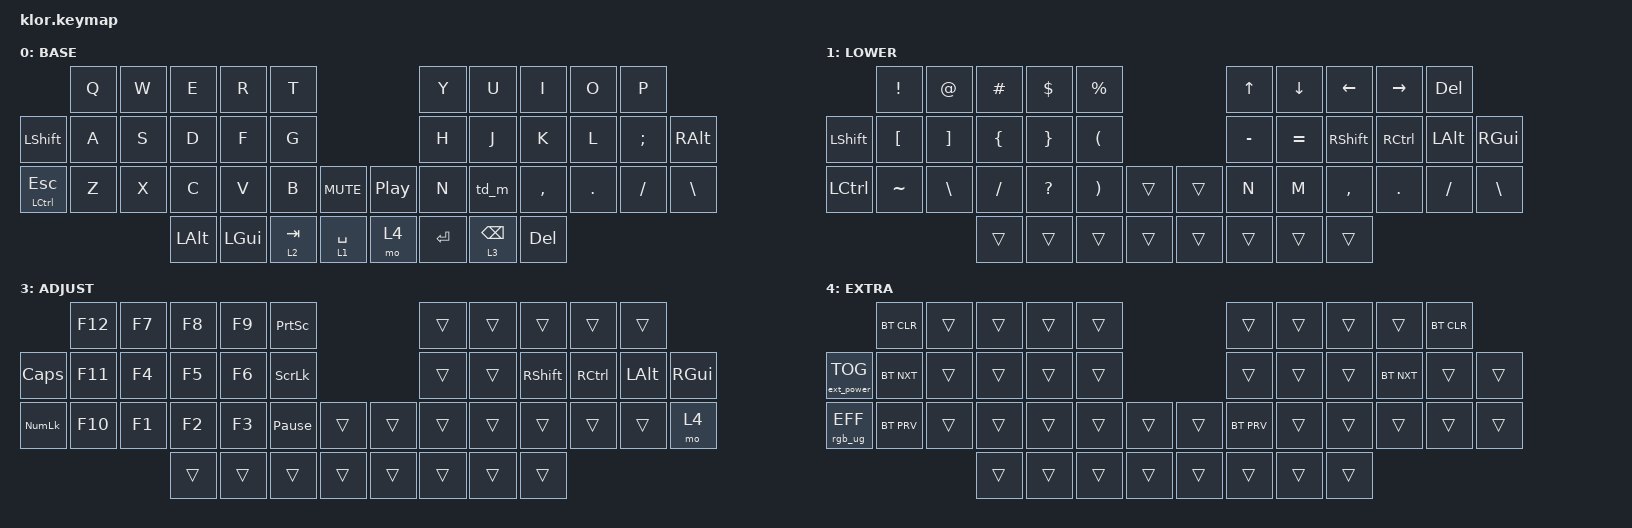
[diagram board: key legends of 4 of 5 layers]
//                               █         █    █            ▄▄▄▀▀▀▀▀▀▄▄▄        █▀▀▀▀▀▀▀▀▀▀█
//                               █        █     █          ▄▀            ▀▄      █          █
//                               █       █      █        ▄▀                ▀▄    █          █
//                               █      █       █        █                  █    █          █
//                               █     █        █       █                    █   █          █
//                               █    █         █       █                    █   █▄▄▄▄▄▄▄▄▄▄█
//                               █   █ █        █       █                    █   █      █
//                               █  █   █       █        █                  █    █       █
//                               █ █     █      █        ▀▄                ▄▀    █        █
//                               ██       █     █          ▀▄            ▄▀      █         █
//                               █         █    █▄▄▄▄▄▄▄▄    ▀▀▀▄▄▄▄▄▄▀▀▀        █          █
//
// ▄▄▄▄▄▄▄▄▄▄▄▄▄▄▄▄▄▄▄▄▄▄▄▄▄▄▄▄▄▄▄▄▄▄▄▄▄▄▄▄▄▄▄▄▄▄▄▄▄▄▄▄▄▄▄▄▄▄▄▄▄▄▄▄▄▄▄▄▄▄▄▄▄▄▄▄▄▄▄▄▄▄▄▄▄▄▄▄▄▄▄▄▄▄▄▄▄▄▄▄▄▄▄▄▄▄▄▄▄▄▄▄▄▄▄▄▄▄▄▄▄▄▄▄▄

#include <behaviors.dtsi>
#include <dt-bindings/zmk/bt.h>
#include <dt-bindings/zmk/ext_power.h>
#include <dt-bindings/zmk/keys.h>
#include <dt-bindings/zmk/rgb.h>

#define BASE   0
#define LOWER  1
#define RAISE  2
#define ADJUST 3
#define EXTRA  4

/ {
    behaviors {
        // Tap-Dance для клавиши M: 1 нажатие = M, 2 нажатия = Ъ (])
        td_m: tap_dance_m {
            compatible = "zmk,behavior-tap-dance";
            #binding-cells = <0>;
            tapping-term-ms = <200>;
            bindings = <&kp M>, <&kp RBRC>;
        };

        // Макрос для смены языка (Win+Space)
        lang_sw: lang_switch {
            compatible = "zmk,behavior-macro";
            #binding-cells = <0>;
            bindings = 
                <&macro_press &kp LGUI>,
                <&macro_tap &kp SPACE>,
                <&macro_release &kp LGUI>;
        };
    };

    combos {
        compatible = "zmk,combos";

        // Комбо Q+E (позиции 0 и 2)
        combo_lang {
            timeout-ms = <100>;
            key-positions = <0 2>;
            bindings = <&lang_sw>;
        };
    };

    keymap {
        compatible = "zmk,keymap";

        // ==========================================
        // Layer 0 (BASE)
        // ==========================================
        base_layer {
            label = "BASE";
            bindings = <
                &kp Q  &kp W  &kp E      &kp R        &kp T                          &kp Y    &kp U        &kp I      &kp O    &kp P
&kp LSHFT       &kp A  &kp S  &kp D      &kp F        &kp G                          &kp H    &kp J        &kp K      &kp L    &kp SEMICOLON  &kp RALT
&mt LCTRL ESC   &kp Z  &kp X  &kp C      &kp V        &kp B      &kp C_MUTE &kp C_PP  &kp N    &td_m        &kp COMMA  &kp DOT  &kp SLASH      &kp BSLH
                              &kp LALT   &kp LGUI   &lt 2 TAB  &lt 1 SPACE&mo 4      &kp ENTER  &lt 3 BSPC &kp DEL
            >;
            sensor-bindings = <&inc_dec_kp C_VOL_UP C_VOL_DN &inc_dec_kp C_PREV C_NEXT>;
        };

        // ==========================================
        // Layer 1 (LOWER) - Символы
        // ==========================================
        lower_layer {
            label = "LOWER";
            bindings = <
                &kp EXCL  &kp AT    &kp HASH  &kp DLLR    &kp PRCNT                      &kp UP   &kp DOWN     &kp LEFT   &kp RIGHT&kp DEL
&kp LSHFT       &kp LBKT  &kp RBKT  &kp LBRC  &kp RBRC     &kp LPAR                       &kp MINUS&kp EQUAL    &kp RSHFT  &kp RCTRL&kp LALT      &kp RGUI
&kp LCTRL       &kp TILDE &kp BSLH  &kp SLASH &kp QMARK    &kp RPAR    &trans    &trans    &kp N    &kp M        &kp COMMA  &kp DOT  &kp SLASH      &kp BSLH
                              &trans     &trans       &trans     &trans     &trans     &trans     &trans     &trans
            >;
            sensor-bindings = <&inc_dec_kp C_VOL_UP C_VOL_DN &inc_dec_kp C_PREV C_NEXT>;
        };

        // ==========================================
        // Layer 2 (RAISE) - Numpad
        // ==========================================
        raise_layer {
            label = "RAISE";
            bindings = <
                &kp LSHFT &kp AMPS  &kp ASTRK &kp LPAR   &kp RPAR                       &kp KP_N7&kp KP_N8    &kp KP_N9  &kp KP_PLUS &kp KP_MINUS
&kp LSHFT       &kp PRCNT &kp CARET &kp AT     &kp HASH     &kp EXCL                       &kp KP_N4&kp KP_N5    &kp KP_N6  &kp KP_MULTIPLY&kp KP_DIVIDE
&kp LSHFT       &kp DLLR  &kp EXCL  &kp TILDE  &kp BSLH     &kp UNDER  &trans    &trans    &kp KP_N1&kp KP_N2    &kp KP_N3  &kp KP_N0  &kp KP_DOT     &trans
                              &trans     &trans       &trans     &trans     &trans     &trans     &trans     &trans
            >;
            sensor-bindings = <&inc_dec_kp C_VOL_UP C_VOL_DN &inc_dec_kp C_PREV C_NEXT>;
        };

        // ==========================================
        // Layer 3 (ADJUST) - F-клавиши
        // ==========================================
        adjust_layer {
            label = "ADJUST";
            bindings = <
                &kp F12   &kp F7  &kp F8  &kp F9       &kp PSCRN                      &trans   &trans       &trans     &trans   &trans
&kp CLCK        &kp F11   &kp F4  &kp F5  &kp F6       &kp SLCK                       &trans   &trans       &kp RSHFT  &kp RCTRL&kp LALT      &kp RGUI
&kp KP_NUM      &kp F10   &kp F1  &kp F2  &kp F3       &kp PAUSE_BREAK&trans    &trans    &trans   &trans       &trans     &trans   &trans        &mo 4
                              &trans     &trans       &trans     &trans     &trans     &trans     &trans     &trans
            >;
            sensor-bindings = <&inc_dec_kp C_VOL_UP C_VOL_DN &inc_dec_kp C_PREV C_NEXT>;
        };

        // ==========================================
        // Layer 4 (EXTRA) - Служебный слой
        // ==========================================
        extra_layer {
            label = "EXTRA";
            bindings = <
                &bt BT_CLR &trans  &trans  &trans       &trans                         &trans   &trans       &trans     &trans   &bt BT_CLR
&ext_power EP_TOG &bt BT_NXT &trans  &trans  &trans       &trans                         &trans   &trans       &trans     &bt BT_NXT&trans      &trans
&rgb_ug RGB_EFF &bt BT_PRV &trans  &trans  &trans       &trans   &trans    &trans    &bt BT_PRV&trans       &trans     &trans   &trans        &trans
                              &trans     &trans       &trans     &trans     &trans     &trans     &trans     &trans
            >;
            sensor-bindings = <&inc_dec_kp C_VOL_UP C_VOL_DN &inc_dec_kp C_PREV C_NEXT>;
        };
    };
};
